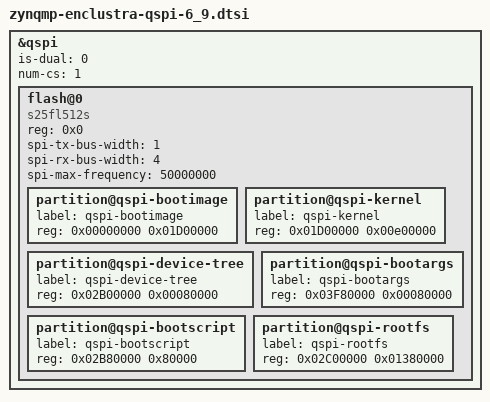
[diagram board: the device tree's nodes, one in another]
&qspi {
	status = "okay";
	is-dual = <0>;
	num-cs = <1>;
	flash@0 {
		compatible = "s25fl512s";
		reg = <0x0>;
		spi-tx-bus-width = <1>;
		spi-rx-bus-width = <4>;
		spi-max-frequency = <50000000>;
		#address-cells = <1>;
		#size-cells = <1>;
		partition@qspi-bootimage {
			label = "qspi-bootimage";
			reg = <0x00000000 0x01D00000>;
		};
		partition@qspi-kernel {
			label = "qspi-kernel";
			reg = <0x01D00000 0x00e00000>;
		};
		partition@qspi-device-tree {
			label = "qspi-device-tree";
			reg = <0x02B00000 0x00080000>;
		};
		partition@qspi-bootargs {
			label = "qspi-bootargs";
			reg = <0x03F80000 0x00080000>;
		};
		partition@qspi-bootscript {
			label = "qspi-bootscript";
			reg = <0x02B80000 0x80000>;
		};
		partition@qspi-rootfs {
			label = "qspi-rootfs";
			reg = <0x02C00000 0x01380000>;
		};
	};
};
